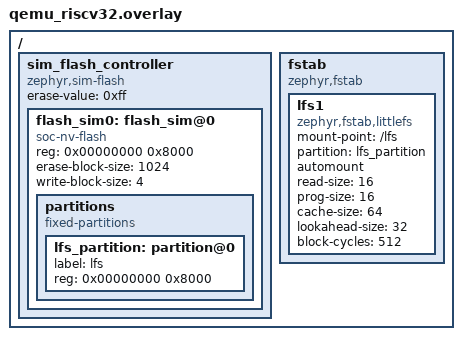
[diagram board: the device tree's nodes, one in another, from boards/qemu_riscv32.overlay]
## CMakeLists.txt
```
# SPDX-License-Identifier: Apache-2.0
cmake_minimum_required(VERSION 3.20.0)
find_package(Zephyr REQUIRED HINTS $ENV{ZEPHYR_BASE})
project(__name___tests)

set(LIB ${CMAKE_CURRENT_LIST_DIR}/../../lib)
target_include_directories(app PRIVATE ${LIB}/datalog)
target_sources(app PRIVATE ${LIB}/datalog/datalog.c src/test_datalog.c)
```

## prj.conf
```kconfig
CONFIG_ZTEST=y
CONFIG_ZTEST_STACK_SIZE=4096
CONFIG_FLASH=y
CONFIG_FLASH_MAP=y
CONFIG_FILE_SYSTEM=y
CONFIG_FILE_SYSTEM_LITTLEFS=y
```

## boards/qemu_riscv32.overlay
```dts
/* qemu: simulated flash with a 32 KiB partition, LittleFS mounted at /lfs on boot */
/ {
	sim_flash_controller: sim_flash_controller {
		compatible = "zephyr,sim-flash";
		#address-cells = <1>;
		#size-cells = <1>;
		erase-value = <0xff>;

		flash_sim0: flash_sim@0 {
			compatible = "soc-nv-flash";
			reg = <0x00000000 0x8000>;
			erase-block-size = <1024>;
			write-block-size = <4>;

			partitions {
				compatible = "fixed-partitions";
				#address-cells = <1>;
				#size-cells = <1>;

				lfs_partition: partition@0 {
					label = "lfs";
					reg = <0x00000000 0x8000>;
				};
			};
		};
	};

	fstab {
		compatible = "zephyr,fstab";
		lfs1: lfs1 {
			compatible = "zephyr,fstab,littlefs";
			mount-point = "/lfs";
			partition = <&lfs_partition>;
			automount;
			read-size = <16>;
			prog-size = <16>;
			cache-size = <64>;
			lookahead-size = <32>;
			block-cycles = <512>;
		};
	};
};
```

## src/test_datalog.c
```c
#include <zephyr/ztest.h>
#include <zephyr/fs/fs.h>
#include "datalog.h"

FS_FSTAB_DECLARE_ENTRY(DT_NODELABEL(lfs1));

static void before(void *f)
{
	ARG_UNUSED(f);
	fs_unlink(DATALOG_DIR "/log.bin");
	fs_unlink(DATALOG_DIR "/log.old");
}

ZTEST_SUITE(datalog, NULL, NULL, before, NULL, NULL);

ZTEST(datalog, test_append_and_read)
{
	struct record r;

	for (int i = 0; i < 5; i++) {
		zassert_ok(datalog_append(i * 100));
	}
	zassert_equal(datalog_count(), 5);
	zassert_ok(datalog_read(3, &r));
	zassert_equal(r.value, 300);
	zassert_equal(datalog_read(5, &r), -ENOENT);
}

ZTEST(datalog, test_rotation)
{
	struct fs_dirent st;
	uint32_t rot = datalog_rotations();

	for (int i = 0; i < DATALOG_MAX_RECORDS + 3; i++) {
		zassert_ok(datalog_append(i), "append %d", i);
	}
	zassert_equal(datalog_rotations(), rot + 1);
	zassert_equal(datalog_count(), 3);
	zassert_ok(fs_stat(DATALOG_DIR "/log.old", &st));
	zassert_equal(st.size, DATALOG_MAX_RECORDS * sizeof(struct record));
}

ZTEST(datalog, test_survives_remount)
{
	struct fs_mount_t *mp = &FS_FSTAB_ENTRY(DT_NODELABEL(lfs1));
	struct record r;

	zassert_ok(datalog_append(777));
	zassert_ok(fs_unmount(mp));
	zassert_ok(fs_mount(mp));
	zassert_equal(datalog_count(), 1);
	zassert_ok(datalog_read(0, &r));
	zassert_equal(r.value, 777);
}
```
